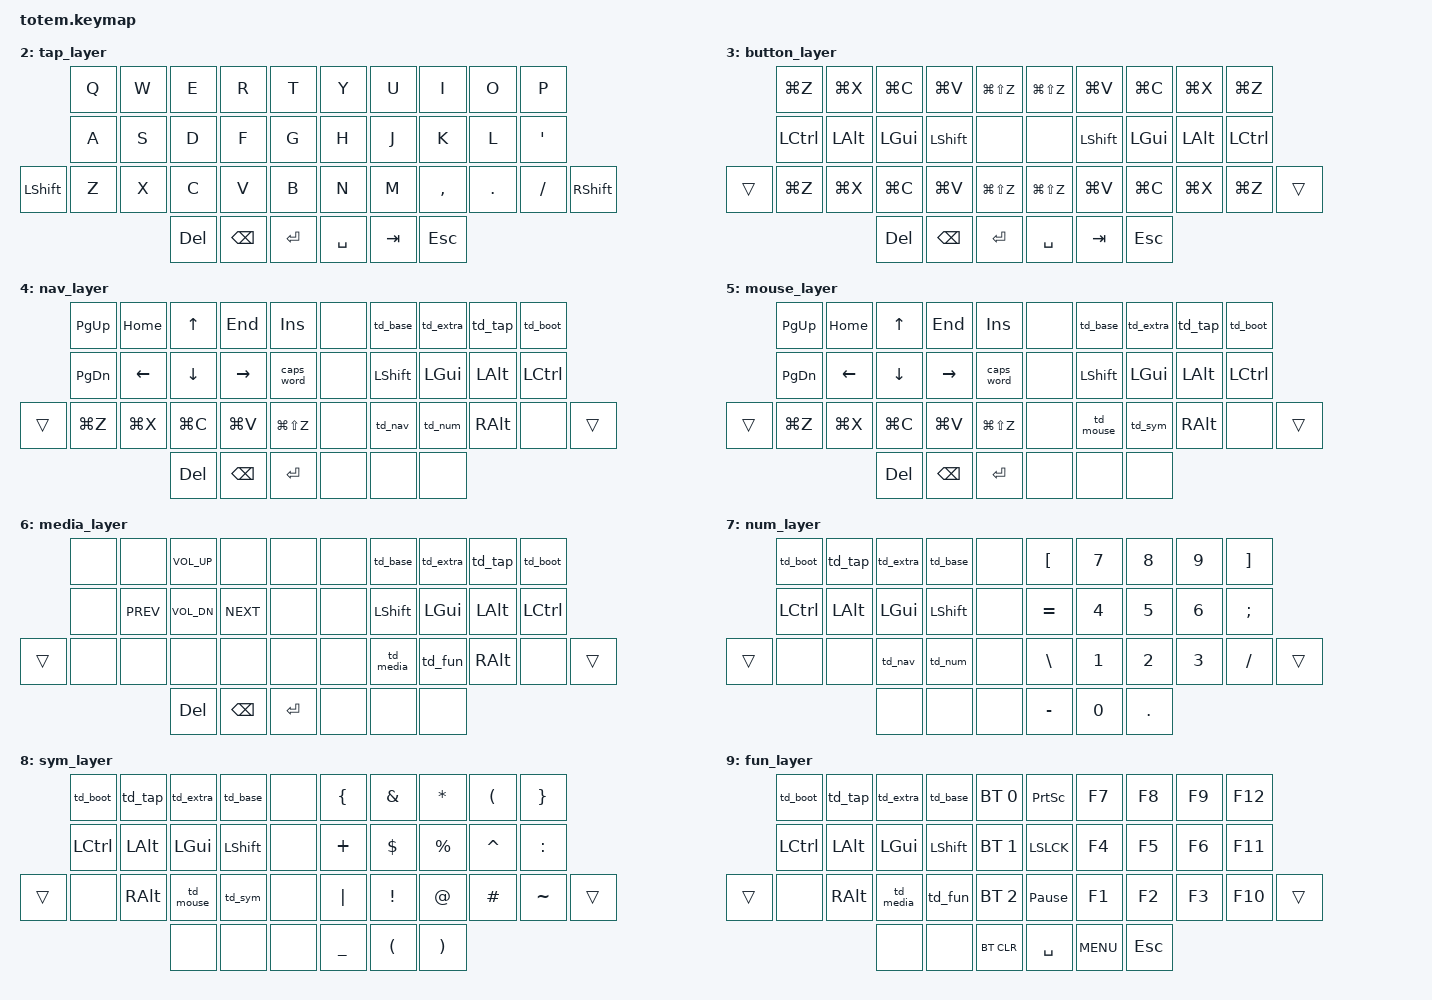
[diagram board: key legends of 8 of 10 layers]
// Copyright (c) 2022 The ZMK Contributors
// SPDX-License-Identifier: MIT

#include <behaviors.dtsi>
#include <dt-bindings/zmk/keys.h>
#include <dt-bindings/zmk/bt.h>
#include <dt-bindings/zmk/pointing.h>

#define BASE   = 0
#define EXTRA  = 1
#define TAP    = 2
#define BUTTON = 3
#define NAV    = 4
#define MOUSE  = 5
#define MEDIA  = 6
#define NUM    = 7
#define SYM    = 8
#define FUN    = 9


// Home row mods macro
#define HRML(k1,k2,k3,k4) &ht LCTRL k1  &ht LALT k2  &ht LGUI k3  &ht LSHFT k4  
#define HRMR(k1,k2,k3,k4) &ht RSHFT k1  &ht RGUI k2  &ht RALT k3  &ht RCTRL k4
// Thumb row layer tap macro
#define TRLL(k1,k2,k3) &lt 9 k1  &lt 8 k2  &lt 7 k3
#define TRLR(k1,k2,k3) &lt 4 k1  &lt 5 k2  &lt 6 k3


/ {
    // miryoku-style thumb-combos
    combos {
        compatible = "zmk,combos";
        
        combo_lthumb_base {
            timeout-ms = <50>;
            key-positions = <30 31>;
            layers = <0>;
            bindings = <&lt 9 DEL>;
        };
        
        combo_rthumb_base {
            timeout-ms = <50>;
            key-positions = <32 33>;
            layers = <0>;
            bindings = <&lt 6 ESC>;
        };
        
        combo_lthumb_extra {
            timeout-ms = <50>;
            key-positions = <30 31>;
            layers = <1>;
            bindings = <&lt 9 DEL>;
        };
        
        combo_rthumb_extra {
            timeout-ms = <50>;
            key-positions = <32 33>;
            layers = <1>;
            bindings = <&lt 6 ESC>;
        };

        combo_lthumb_button {
            timeout-ms = <50>;
            key-positions = <30 31>;
            layers = <3>;
            bindings = <&mkp MCLK>;
        };
        
        combo_rthumb_button {
            timeout-ms = <50>;
            key-positions = <32 33>;
            layers = <3>;
            bindings = <&mkp MCLK>;
        };
        
        combo_lthumb_nav {
            timeout-ms = <50>;
            key-positions = <30 31>;
            layers = <4>;
            bindings = <&kp DEL>;
        };
        
        combo_lthumb_mouse {
            timeout-ms = <50>;
            key-positions = <30 31>;
            layers = <5>;
            bindings = <&mkp MCLK>;
        };
        
        combo_lthumb_media {
            timeout-ms = <50>;
            key-positions = <30 31>;
            layers = <6>;
            bindings = <&kp C_MUTE>;
        };
        
        combo_rthumb_num {
            timeout-ms = <50>;
            key-positions = <32 33>;
            layers = <7>;
            bindings = <&kp DOT>;
        };
        
        combo_rthumb_sym {
            timeout-ms = <50>;
            key-positions = <32 33>;
            layers = <8>;
            bindings = <&kp RPRN>;
        };
   };

    behaviors {
        ht: hold_tap {
            compatible = "zmk,behavior-hold-tap";
            #binding-cells = <2>;
            flavor = "tap-preferred";
            tapping-term-ms = <220>;
            quick-tap-ms = <150>;
            require-prior-idle-ms = <100>;
            bindings = <&kp>, <&kp>;
        };

        td_boot: tap_dance_boot {
            compatible = "zmk,behavior-tap-dance";
            #binding-cells = <0>;
            tapping-term-ms = <200>;
            bindings = <&none>, <&bootloader>;
        };

        td_base: tap_dance_base {
            compatible = "zmk,behavior-tap-dance";
            #binding-cells = <0>;
            tapping-term-ms = <200>;
            bindings = <&none>, <&to 0>;
        };

        td_extra: tap_dance_extra {
            compatible = "zmk,behavior-tap-dance";
            #binding-cells = <0>;
            tapping-term-ms = <200>;
            bindings = <&none>, <&to 1>;
        };

        td_tap: tap_dance_tap {
            compatible = "zmk,behavior-tap-dance";
            #binding-cells = <0>;
            tapping-term-ms = <200>;
            bindings = <&none>, <&to 2>;
        };

        td_nav: tap_dance_nav {
            compatible = "zmk,behavior-tap-dance";
            #binding-cells = <0>;
            tapping-term-ms = <200>;
            bindings = <&none>, <&to 4>;
        };

        td_mouse: tap_dance_mouse {
            compatible = "zmk,behavior-tap-dance";
            #binding-cells = <0>;
            tapping-term-ms = <200>;
            bindings = <&none>, <&to 5>;
        };

        td_media: tap_dance_media {
            compatible = "zmk,behavior-tap-dance";
            #binding-cells = <0>;
            tapping-term-ms = <200>;
            bindings = <&none>, <&to 6>;
        };

        td_num: tap_dance_num {
            compatible = "zmk,behavior-tap-dance";
            #binding-cells = <0>;
            tapping-term-ms = <200>;
            bindings = <&none>, <&to 7>;
        };

        td_sym: tap_dance_sym {
            compatible = "zmk,behavior-tap-dance";
            #binding-cells = <0>;
            tapping-term-ms = <200>;
            bindings = <&none>, <&to 8>;
        };

        td_fun: tap_dance_fun {
            compatible = "zmk,behavior-tap-dance";
            #binding-cells = <0>;
            tapping-term-ms = <200>;
            bindings = <&none>, <&to 9>;
        };
    };

    // no tri-layer
    //conditional_layers {
    //    compatible = "zmk,conditional-layers";
    //    tri_layer {
    //        if-layers = <1 2>;
    //        then-layer = <3>;
    //    };
    //};

    keymap {
        compatible = "zmk,keymap";
        base_layer {
            bindings = <
        //           ╭──────────┬──────────┬──────────┬──────────┬──────────╮   ╭──────────┬──────────┬──────────┬──────────┬──────────╮
                         &kp Q      &kp W      &kp E      &kp R      &kp T          &kp Y      &kp U      &kp I      &kp O      &kp P
        //           ├──────────┼──────────┼──────────┼──────────┼──────────┤   ├──────────┼──────────┼──────────┼──────────┼──────────┤
                        HRML(A,        S,         D,         F)     &kp G          &kp H      HRMR(J,        K,         L,        SQT)
        //╭──────────├──────────┼──────────┼──────────┼──────────┼──────────┤   ├──────────┼──────────┼──────────┼──────────┼──────────┼──────────╮
           &kp LSHFT    &kp Z      &kp X      &kp C      &kp V      &kp B          &kp N      &kp M     &kp COMMA  &kp DOT    &kp FSLH   &kp RSHFT
        //╰──────────┴──────────┴──────────┼──────────┼──────────┼──────────┤   ├──────────┼──────────┼──────────┼──────────┴──────────┴──────────╯
                                            TRLL(DEL,     BKSP,     ENTER  )     TRLR(SPACE,   TAB,       ESC   )
        //                                 ╰──────────┴──────────┴──────────╯   ╰──────────┴──────────┴──────────╯
            >;
        };

        extra_layer {
            bindings = <
        //           ╭──────────┬──────────┬──────────┬──────────┬──────────╮   ╭──────────┬──────────┬──────────┬──────────┬──────────╮
                         &kp Q      &kp W      &kp E      &kp R      &kp T          &kp Y      &kp U      &kp I      &kp O      &kp P
        //           ├──────────┼──────────┼──────────┼──────────┼──────────┤   ├──────────┼──────────┼──────────┼──────────┼──────────┤
                        HRML(A,        S,         D,         F)     &kp G          &kp H      HRMR(J,        K,         L,        SQT)
        //╭──────────├──────────┼──────────┼──────────┼──────────┼──────────┤   ├──────────┼──────────┼──────────┼──────────┼──────────┼──────────╮
            &kp ESC     &kp Z      &kp X      &kp C      &kp V      &kp B          &kp N      &kp M     &kp COMMA  &kp DOT    &kp FSLH   &kp ENTER
        //╰──────────┴──────────┴──────────┼──────────┼──────────┼──────────┤   ├──────────┼──────────┼──────────┼──────────┴──────────┴──────────╯
                                            TRLL(DEL,     BKSP,     ENTER  )     TRLR(SPACE,   TAB,       ESC   )
        //                                 ╰──────────┴──────────┴──────────╯   ╰──────────┴──────────┴──────────╯
            >;
        };


        // based on miryoku tap QWERTY flip
        tap_layer {
            bindings = <
        //╭──────────┬──────────┬──────────┬──────────┬──────────╮   ╭──────────┬──────────┬──────────┬──────────┬──────────╮
             &kp Q      &kp W      &kp E      &kp R      &kp T          &kp Y      &kp U      &kp I      &kp O      &kp P
        //├──────────┼──────────┼──────────┼──────────┼──────────┤   ├──────────┼──────────┼──────────┼──────────┼──────────┤
             &kp A      &kp S      &kp D      &kp F      &kp G          &kp H      &kp J      &kp K      &kp L     &kp QUOT
        //├──────────┼──────────┼──────────┼──────────┼──────────┤   ├──────────┼──────────┼──────────┼──────────┼──────────┤
&kp LSHFT    &kp Z      &kp X      &kp C      &kp V      &kp B          &kp N      &kp M     &kp COMMA   &kp DOT    &kp FSLH  &kp RSHFT
        //╰──────────┴──────────┴──────────┼──────────┼──────────┤   ├──────────┼──────────┼──────────┴──────────┴──────────╯
                                   &kp DEL   &kp BKSP  &kp ENTER      &kp SPACE   &kp TAB    &kp ESC
        //                                 ╰──────────┴──────────╯   ╰──────────┴──────────╯
            >;
        };

        button_layer {
            bindings = <
        //╭──────────┬──────────┬──────────┬──────────┬──────────╮   ╭──────────┬──────────┬──────────┬──────────┬──────────╮
           &kp LG(Z)  &kp LG(X)  &kp LG(C)  &kp LG(V) &kp LG(LS(Z)) &kp LG(LS(Z)) &kp LG(V)  &kp LG(C)  &kp LG(X)  &kp LG(Z)
        //├──────────┼──────────┼──────────┼──────────┼──────────┤   ├──────────┼──────────┼──────────┼──────────┼──────────┤
           &kp LCTRL   &kp LALT   &kp LGUI  &kp LSHFT    &none          &none    &kp LSHFT   &kp LGUI   &kp LALT   &kp LCTL
        //├──────────┼──────────┼──────────┼──────────┼──────────┤   ├──────────┼──────────┼──────────┼──────────┼──────────┤
  &trans   &kp LG(Z)  &kp LG(X)  &kp LG(C)  &kp LG(V) &kp LG(LS(Z)) &kp LG(LS(Z)) &kp LG(V)  &kp LG(C)  &kp LG(X)  &kp LG(Z)   &trans
        //╰──────────┴──────────┴──────────┼──────────┼──────────┤   ├──────────┼──────────┼──────────┴──────────┴──────────╯
                                  &kp DEL    &kp BKSP  &kp ENTER      &kp SPACE   &kp TAB    &kp ESC
        //                                 ╰──────────┴──────────╯   ╰──────────┴──────────╯
            >;
        };

        // based on MIRYOKU_ALTERNATIVES_NAV_INVERTEDT_FLIP  and  MIRYOKU_CLIPBOARD_MAC
        nav_layer {
            bindings = <
        //╭──────────┬──────────┬──────────┬──────────┬──────────╮   ╭──────────┬──────────┬──────────┬──────────┬──────────╮
           &kp PG_UP   &kp HOME   &kp UP      &kp END   &kp INS         &none     &td_base   &td_extra  &td_tap    &td_boot
        //├──────────┼──────────┼──────────┼──────────┼──────────┤   ├──────────┼──────────┼──────────┼──────────┼──────────┤
           &kp PG_DN   &kp LEFT   &kp DOWN   &kp RIGHT &caps_word       &none    &kp LSHFT   &kp LGUI   &kp LALT   &kp LCTL
        //├──────────┼──────────┼──────────┼──────────┼──────────┤   ├──────────┼──────────┼──────────┼──────────┼──────────┤
   &trans   &kp LG(Z)  &kp LG(X)  &kp LG(C)  &kp LG(V) &kp LG(LS(Z))     &none     &td_nav    &td_num    &kp RALT    &none    &trans
        //╰──────────┴──────────┴──────────┼──────────┼──────────┤   ├──────────┼──────────┼──────────┴──────────┴──────────╯
                                  &kp DEL    &kp BKSP  &kp ENTER        &none      &none      &none
        //                                 ╰──────────┴──────────╯   ╰──────────┴──────────╯
            >;
        };
        
        // based on MIRYOKU_ALTERNATIVES_MOUSE_INVERTEDT_FLIP  and  MIRYOKU_CLIPBOARD_MAC
        mouse_layer {
            bindings = <
        //╭────────────────┬────────────────┬────────────────┬────────────────┬──────────╮   ╭──────────┬──────────┬──────────┬──────────┬──────────╮
//            &msc SCROLL_UP  &msc SCROLL_LEFT   &mmv MOVE_UP  &msc SCROLL_RIGHT   &none          &none     &td_base   &td_extra  &td_tap    &td_boot
              &kp PG_UP       &kp HOME           &kp UP        &kp END          &kp INS         &none     &td_base   &td_extra  &td_tap    &td_boot
        //├────────────────┼────────────────┼────────────────┼────────────────┼──────────┤   ├──────────┼──────────┼──────────┼──────────┼──────────┤
//           &msc SCROLL_DOWN  &mmv MOVE_LEFT   &mmv MOVE_DOWN  &mmv MOVE_RIGHT    &none          &none    &kp LSHFT   &kp LGUI   &kp LALT   &kp LCTL
             &kp PG_DN         &kp LEFT         &kp DOWN        &kp RIGHT      &caps_word       &none    &kp LSHFT   &kp LGUI   &kp LALT   &kp LCTL
        //├────────────────┼────────────────┼────────────────┼────────────────┼──────────┤   ├──────────┼──────────┼──────────┼──────────┼──────────┤
   &trans     &kp LG(Z)        &kp LG(X)        &kp LG(C)       &kp LG(V)     &kp LG(LS(Z))     &none    &td_mouse   &td_sym    &kp RALT    &none     &trans
        //╰────────────────┴────────────────┴────────────────┼────────────────┼──────────┤   ├──────────┼──────────┼──────────┴──────────┴──────────╯
//                                                                    &mkp RCLK  &mkp LCLK        &none      &none
                                                          &kp DEL    &kp BKSP  &kp ENTER        &none      &none      &none
        //                                                         ╰──────────┴──────────╯   ╰──────────┴──────────╯
            >;
        };

        media_layer {
            bindings = <
        //╭──────────┬──────────┬──────────┬──────────┬──────────╮   ╭──────────┬──────────┬──────────┬──────────┬──────────╮
             &none      &none   &kp C_VOL_UP  &none      &none          &none     &td_base   &td_extra  &td_tap    &td_boot
        //├──────────┼──────────┼──────────┼──────────┼──────────┤   ├──────────┼──────────┼──────────┼──────────┼──────────┤
             &none   &kp C_PREV &kp C_VOL_DN &kp C_NEXT  &none          &none    &kp LSHFT   &kp LGUI   &kp LALT   &kp LCTL
        //├──────────┼──────────┼──────────┼──────────┼──────────┤   ├──────────┼──────────┼──────────┼──────────┼──────────┤
   &trans    &none      &none      &none      &none      &none          &none    &td_media   &td_fun    &kp RALT    &none      &trans
        //╰──────────┴──────────┴──────────┼──────────┼──────────┤   ├──────────┼──────────┼──────────┴──────────┴──────────╯
                                   &kp DEL   &kp BKSP  &kp ENTER         &none      &none     &none
        //                                 ╰──────────┴──────────╯   ╰──────────┴──────────╯
            >;
        };

        num_layer {
            bindings = <
        //╭──────────┬──────────┬──────────┬──────────┬──────────╮   ╭──────────┬──────────┬──────────┬──────────┬──────────╮
            &td_boot   &td_tap   &td_extra   &td_base    &none         &kp LBKT    &kp N7     &kp N8     &kp N9    &kp RBKT
        //├──────────┼──────────┼──────────┼──────────┼──────────┤   ├──────────┼──────────┼──────────┼──────────┼──────────┤
           &kp LCTRL   &kp LALT   &kp LGUI  &kp LSHFT    &none        &kp EQUAL    &kp N4     &kp N5     &kp N6    &kp SEMI
        //├──────────┼──────────┼──────────┼──────────┼──────────┤   ├──────────┼──────────┼──────────┼──────────┼──────────┤
    &trans   &none      &none     &td_nav    &td_num     &none         &kp BSLH    &kp N1     &kp N2     &kp N3    &kp FSLH   &trans
        //╰──────────┴──────────┴──────────┼──────────┼──────────┤   ├──────────┼──────────┼──────────┴──────────┴──────────╯
                                   &none      &none      &none        &kp MINUS    &kp N0     &kp DOT
        //                                 ╰──────────┴──────────╯   ╰──────────┴──────────╯
            >;
        };

        sym_layer {
            bindings = <
        //╭──────────┬──────────┬──────────┬──────────┬──────────╮   ╭──────────┬──────────┬──────────┬──────────┬──────────╮
            &td_boot   &td_tap   &td_extra   &td_base    &none         &kp LBRC   &kp AMPS  &kp ASTRK   &kp LPRN   &kp RBRC
        //├──────────┼──────────┼──────────┼──────────┼──────────┤   ├──────────┼──────────┼──────────┼──────────┼──────────┤
           &kp LCTRL   &kp LALT   &kp LGUI  &kp LSHFT    &none         &kp PLUS   &kp DLLR  &kp PRCNT  &kp CARET  &kp COLON
        //├──────────┼──────────┼──────────┼──────────┼──────────┤   ├──────────┼──────────┼──────────┼──────────┼──────────┤
   &trans    &none     &kp RALT   &td_mouse  &td_sym     &none         &kp PIPE   &kp EXCL   &kp AT     &kp HASH  &kp TILDE   &trans
        //╰──────────┴──────────┴──────────┼──────────┼──────────┤   ├──────────┼──────────┼──────────┴──────────┴──────────╯
                                    &none     &none      &none        &kp UNDER   &kp LPRN   &kp RPRN
        //                                 ╰──────────┴──────────╯   ╰──────────┴──────────╯
            >;
        };

        fun_layer {
            bindings = <
        //╭──────────┬──────────┬──────────┬──────────┬──────────╮   ╭──────────┬──────────┬──────────┬──────────┬──────────╮
            &td_boot   &td_tap   &td_extra   &td_base &bt BT_SEL 0     &kp PSCRN    &kp F7     &kp F8     &kp F9    &kp F12 
        //├──────────┼──────────┼──────────┼──────────┼──────────┤   ├──────────┼──────────┼──────────┼──────────┼──────────┤
           &kp LCTRL   &kp LALT   &kp LGUI  &kp LSHFT &bt BT_SEL 1     &kp LSLCK    &kp F4     &kp F5     &kp F6    &kp F11
        //├──────────┼──────────┼──────────┼──────────┼──────────┤   ├──────────┼──────────┼──────────┼──────────┼──────────┤
   &trans    &none     &kp RALT  &td_media   &td_fun  &bt BT_SEL 2  &kp PAUSE_BREAK &kp F1    &kp F2     &kp F3    &kp F10    &trans
        //╰──────────┴──────────┴──────────┼──────────┼──────────┤   ├──────────┼──────────┼──────────┴──────────┴──────────╯
                                   &none      &none    &bt BT_CLR      &kp SPC   &kp K_MENU  &kp ESC
        //                                 ╰──────────┴──────────╯   ╰──────────┴──────────╯
            >;
        };
    };
};
